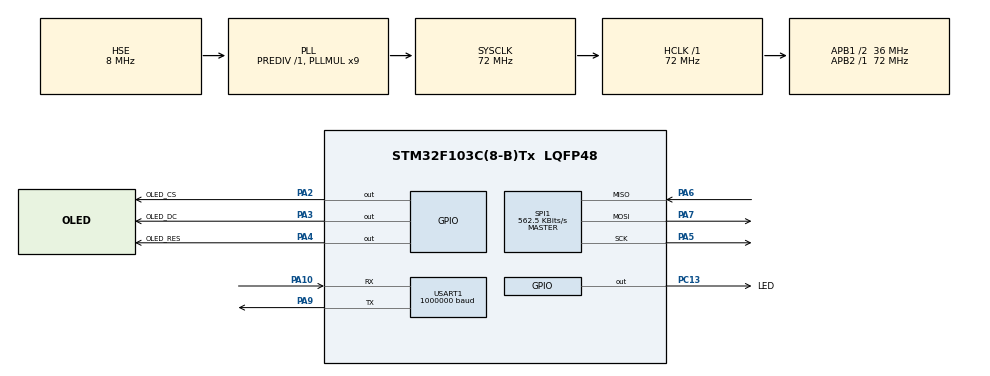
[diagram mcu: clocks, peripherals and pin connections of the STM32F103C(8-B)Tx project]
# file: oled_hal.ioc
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Dma.Request0=USART1_RX
Dma.Request1=USART1_TX
Dma.USART1_RX.0.Direction=DMA_PERIPH_TO_MEMORY
Dma.USART1_RX.0.Instance=DMA1_Channel5
Dma.USART1_RX.0.MemDataAlignment=DMA_MDATAALIGN_BYTE
Dma.USART1_RX.0.MemInc=DMA_MINC_ENABLE
Dma.USART1_RX.0.Mode=DMA_CIRCULAR
Dma.USART1_RX.0.PeriphDataAlignment=DMA_PDATAALIGN_BYTE
Dma.USART1_RX.0.PeriphInc=DMA_PINC_DISABLE
Dma.USART1_RX.0.Priority=DMA_PRIORITY_LOW
Dma.USART1_TX.1.Direction=DMA_MEMORY_TO_PERIPH
Dma.USART1_TX.1.Instance=DMA1_Channel4
Dma.USART1_TX.1.MemDataAlignment=DMA_MDATAALIGN_BYTE
Dma.USART1_TX.1.MemInc=DMA_MINC_ENABLE
Dma.USART1_TX.1.Mode=DMA_NORMAL
Dma.USART1_TX.1.PeriphDataAlignment=DMA_PDATAALIGN_BYTE
Dma.USART1_TX.1.PeriphInc=DMA_PINC_DISABLE
Dma.USART1_TX.1.Priority=DMA_PRIORITY_LOW
Mcu.Family=STM32F1
Mcu.Name=STM32F103C(8-B)Tx
Mcu.Package=LQFP48
NVIC.DMA1_Channel4_IRQn=true\:0\:0\:false\:false\:true\:false\:true
NVIC.DMA1_Channel5_IRQn=true\:3\:0\:true\:false\:true\:false\:true
NVIC.PriorityGroup=NVIC_PRIORITYGROUP_4
NVIC.USART1_IRQn=true\:3\:0\:true\:false\:true\:true\:true
PA10.Mode=Asynchronous
PA10.Signal=USART1_RX
PA13.Mode=Serial_Wire
PA13.Signal=SYS_JTMS-SWDIO
PA14.Mode=Serial_Wire
PA14.Signal=SYS_JTCK-SWCLK
PA2.GPIO_Label=OLED_CS
PA2.GPIO_Speed=GPIO_SPEED_FREQ_HIGH
PA2.Signal=GPIO_Output
PA3.GPIO_Label=OLED_DC
PA3.GPIO_Speed=GPIO_SPEED_FREQ_HIGH
PA3.Signal=GPIO_Output
PA4.GPIO_Label=OLED_RES
PA4.GPIO_Speed=GPIO_SPEED_FREQ_HIGH
PA4.Signal=GPIO_Output
PA5.Mode=Full_Duplex_Master
PA5.Signal=SPI1_SCK
PA6.Mode=Full_Duplex_Master
PA6.Signal=SPI1_MISO
PA7.Mode=Full_Duplex_Master
PA7.Signal=SPI1_MOSI
PA9.Mode=Asynchronous
PA9.Signal=USART1_TX
PC13-TAMPER-RTC.GPIO_Label=LED
PC13-TAMPER-RTC.PinState=GPIO_PIN_RESET
PC13-TAMPER-RTC.Signal=GPIO_Output
PD0-OSC_IN.Mode=HSE-External-Oscillator
PD0-OSC_IN.Signal=RCC_OSC_IN
PD1-OSC_OUT.Mode=HSE-External-Oscillator
PD1-OSC_OUT.Signal=RCC_OSC_OUT
ProjectManager.HeapSize=0x200
ProjectManager.StackSize=0x400
ProjectManager.TargetToolchain=STM32CubeIDE
RCC.AHBFreq_Value=72000000
RCC.APB1CLKDivider=RCC_HCLK_DIV2
RCC.APB1Freq_Value=36000000
RCC.APB1TimFreq_Value=72000000
RCC.APB2Freq_Value=72000000
RCC.APB2TimFreq_Value=72000000
RCC.HCLKFreq_Value=72000000
RCC.PLLMUL=RCC_PLL_MUL9
RCC.PLLSourceVirtual=RCC_PLLSOURCE_HSE
RCC.SYSCLKFreq_VALUE=72000000
RCC.SYSCLKSource=RCC_SYSCLKSOURCE_PLLCLK
RCC.USBFreq_Value=72000000
SPI1.BaudRatePrescaler=SPI_BAUDRATEPRESCALER_128
SPI1.CalculateBaudRate=562.5 KBits/s
SPI1.Direction=SPI_DIRECTION_2LINES
SPI1.Mode=SPI_MODE_MASTER
SPI1.VirtualType=VM_MASTER
USART1.BaudRate=1000000
USART1.VirtualMode=VM_ASYNC
board=custom

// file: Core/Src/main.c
/* USER CODE BEGIN Header */
/**
  ******************************************************************************
  * @file           : main.c
  * @brief          : Main program body
  ******************************************************************************
  * @attention
  *
  * <h2><center>&copy; Copyright (c) 2020 STMicroelectronics.
  * All rights reserved.</center></h2>
  *
  * This software component is licensed by ST under BSD 3-Clause license,
  * the "License"; You may not use this file except in compliance with the
  * License. You may obtain a copy of the License at:
  *                        opensource.org/licenses/BSD-3-Clause
  *
  ******************************************************************************
  */
/* USER CODE END Header */
#include "main.h"
#include "dma.h"
#include "spi.h"
#include "usart.h"
#include "gpio.h"

/* USER CODE BEGIN Includes */
#include "draw_api.h"
#include "test.h"
#include "string.h"
/* USER CODE END Includes */

void SystemClock_Config(void);

int main(void)
{

  /* MCU Configuration--------------------------------------------------------*/

  /* Reset of all peripherals, Initializes the Flash interface and the Systick. */
  HAL_Init();

  /* Configure the system clock */
  SystemClock_Config();

  /* Initialize all configured peripherals */
  MX_GPIO_Init();
  MX_DMA_Init();
  MX_SPI1_Init();
  MX_USART1_UART_Init();
  /* USER CODE BEGIN 2 */
  InitGraph();
  badapple_init();
//DrawBitmap(0,0,Smile,128,64);
//DrawRoundRect(0,0,30,30,6);
  //demo();
  //UpdateScreen();

  /* USER CODE END 2 */

  /* Infinite loop */
  while (1)
  {

  }
}

void SystemClock_Config(void)
{
  RCC_OscInitTypeDef RCC_OscInitStruct = {0};
  RCC_ClkInitTypeDef RCC_ClkInitStruct = {0};

  /** Initializes the RCC Oscillators according to the specified parameters
  * in the RCC_OscInitTypeDef structure.
  */
  RCC_OscInitStruct.OscillatorType = RCC_OSCILLATORTYPE_HSE;
  RCC_OscInitStruct.HSEState = RCC_HSE_ON;
  RCC_OscInitStruct.HSEPredivValue = RCC_HSE_PREDIV_DIV1;
  RCC_OscInitStruct.HSIState = RCC_HSI_ON;
  RCC_OscInitStruct.PLL.PLLState = RCC_PLL_ON;
  RCC_OscInitStruct.PLL.PLLSource = RCC_PLLSOURCE_HSE;
  RCC_OscInitStruct.PLL.PLLMUL = RCC_PLL_MUL9;
  if (HAL_RCC_OscConfig(&RCC_OscInitStruct) != HAL_OK)
  {
    Error_Handler();
  }
  /** Initializes the CPU, AHB and APB buses clocks
  */
  RCC_ClkInitStruct.ClockType = RCC_CLOCKTYPE_HCLK|RCC_CLOCKTYPE_SYSCLK
                              |RCC_CLOCKTYPE_PCLK1|RCC_CLOCKTYPE_PCLK2;
  RCC_ClkInitStruct.SYSCLKSource = RCC_SYSCLKSOURCE_PLLCLK;
  RCC_ClkInitStruct.AHBCLKDivider = RCC_SYSCLK_DIV1;
  RCC_ClkInitStruct.APB1CLKDivider = RCC_HCLK_DIV2;
  RCC_ClkInitStruct.APB2CLKDivider = RCC_HCLK_DIV1;

  if (HAL_RCC_ClockConfig(&RCC_ClkInitStruct, FLASH_LATENCY_2) != HAL_OK)
  {
    Error_Handler();
  }
}

/* USER CODE BEGIN 4 */
void HAL_UART_RxCpltCallback(UART_HandleTypeDef *huart)
{
    badapple();
}

/* USER CODE END 4 */

void Error_Handler(void)
{
}

/************************ (C) COPYRIGHT STMicroelectronics *****END OF FILE****/
